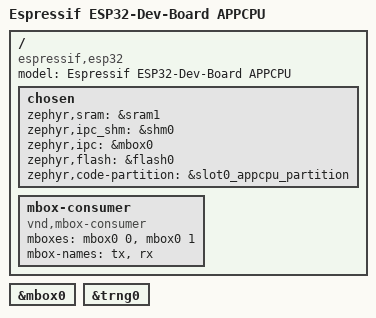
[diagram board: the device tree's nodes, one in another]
/*
 * Copyright (c) 2023-2025 Espressif Systems (Shanghai) Co., Ltd.
 *
 * SPDX-License-Identifier: Apache-2.0
 */
/dts-v1/;

#include <espressif/esp32/esp32_appcpu.dtsi>
#include <espressif/partitions_0x1000_amp_4M.dtsi>

/ {
	model = "Espressif ESP32-Dev-Board APPCPU";
	compatible = "espressif,esp32";

	chosen {
		zephyr,sram = &sram1;
		zephyr,ipc_shm = &shm0;
		zephyr,ipc = &mbox0;
		zephyr,flash = &flash0;
		zephyr,code-partition = &slot0_appcpu_partition;
	};

	mbox-consumer {
		compatible = "vnd,mbox-consumer";
		mboxes = <&mbox0 0>, <&mbox0 1>;
		mbox-names = "tx", "rx";
	};
};

&mbox0 {
	status = "okay";
};

&trng0 {
	status = "okay";
};
